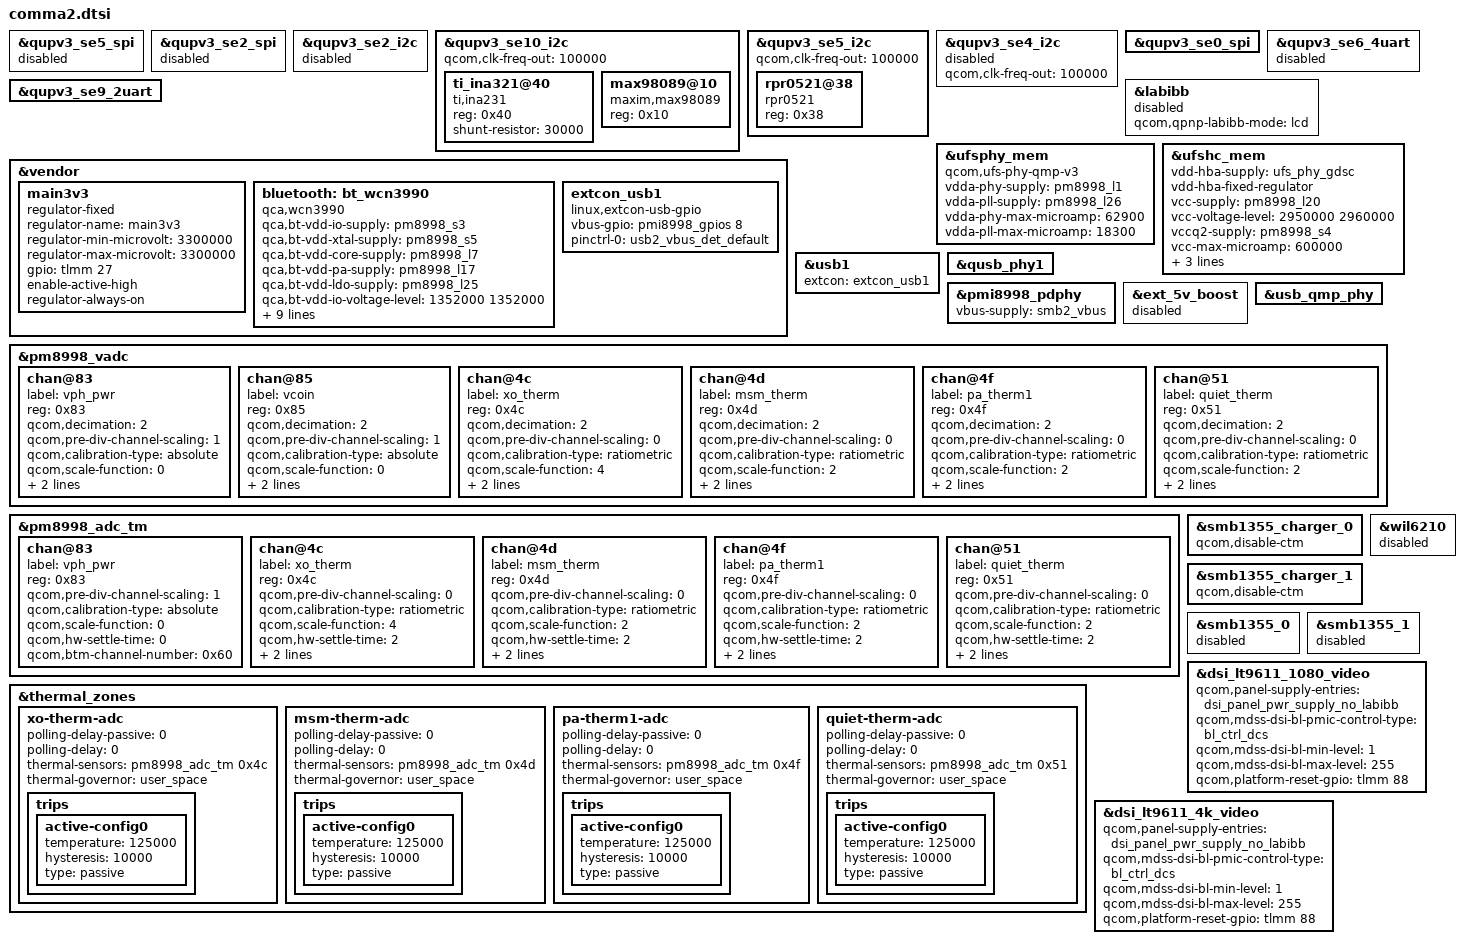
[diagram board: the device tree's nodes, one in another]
#include <dt-bindings/gpio/gpio.h>
#include "sdm845-pmic-overlay.dtsi"
#include "sdm845-pinctrl-overlay.dtsi"
#include "sdm845-camera-sensor-mtp.dtsi"

/* disable the SPI */
&qupv3_se5_spi {
	status = "disabled";
};

&qupv3_se2_spi {
	status = "disabled";
};

&qupv3_se2_i2c {
	status = "disabled";
};

/* audio and power monitor(ina230) I2C, /dev/i2c-0 */
&qupv3_se10_i2c {
  status = "ok";
  qcom,clk-freq-out = <100000>;

  #include "smb1355.dtsi"

  ti_ina321@40 {
    compatible = "ti,ina231";
    reg = <0x40>;
    /* value is 30mOhm, measured in uohms */
    shunt-resistor = <30000>;
  };

  max98089@10 {
    compatible = "maxim,max98089";
    reg = <0x10>;  /* slave address 0x20 for write, 0x21 for read */
    status = "okay";
  };
};

/* light(RPR-0521RS) and touch panel I2C, /dev/i2c-2 */
&qupv3_se5_i2c {
  status = "ok";
  qcom,clk-freq-out = <100000>;

  rpr0521@38 {
    compatible = "rpr0521";
    reg = <0x38>;
  };
};

/* second home of the sensors besides SSC, BLSP4 on tici */
&qupv3_se4_i2c {
  status = "disabled";
  //status = "ok";
  qcom,clk-freq-out = <100000>;
};

/* panda SPI */
&qupv3_se0_spi {
	status = "ok";
};

/* GPS UART */
&qupv3_se6_4uart {
	status = "disabled";
};

/* debug UART */
&qupv3_se9_2uart {
	status = "ok";
};

/* regulators */

&vendor {
  main3v3: main3v3 {
    status = "ok";

    compatible = "regulator-fixed";
    regulator-name = "main3v3";
    regulator-min-microvolt = <3300000>;
    regulator-max-microvolt = <3300000>;

    gpio = <&tlmm 27 0>;
    enable-active-high;
    regulator-always-on;
  };
};

/* IMUs are on SSC i2c, have to interact with that firmware */

&vendor {
	bluetooth: bt_wcn3990 {
		compatible = "qca,wcn3990";
		qca,bt-vdd-io-supply = <&pm8998_s3>;
		qca,bt-vdd-xtal-supply = <&pm8998_s5>;
		qca,bt-vdd-core-supply = <&pm8998_l7>;
		qca,bt-vdd-pa-supply = <&pm8998_l17>;
		qca,bt-vdd-ldo-supply = <&pm8998_l25>;

		qca,bt-vdd-io-voltage-level = <1352000 1352000>;
		qca,bt-vdd-xtal-voltage-level = <2040000 2040000>;
		qca,bt-vdd-core-voltage-level = <1800000 1800000>;
		qca,bt-vdd-pa-voltage-level = <1304000 1304000>;
		qca,bt-vdd-ldo-voltage-level = <3312000 3312000>;

		qca,bt-vdd-io-current-level = <1>; /* LPM/PFM */
		qca,bt-vdd-xtal-current-level = <1>; /* LPM/PFM */
		qca,bt-vdd-core-current-level = <1>; /* LPM/PFM */
		qca,bt-vdd-pa-current-level = <1>; /* LPM/PFM */
		qca,bt-vdd-ldo-current-level = <1>; /* LPM/PFM */
	};

	extcon_usb1: extcon_usb1 {
		compatible = "linux,extcon-usb-gpio";
		vbus-gpio = <&pmi8998_gpios 8 GPIO_ACTIVE_HIGH>;

		pinctrl-names = "default";
		pinctrl-0 = <&usb2_vbus_det_default>;
	};
};

&labibb {
	status = "disabled";
	qcom,qpnp-labibb-mode = "lcd";
};

&ufsphy_mem {
	compatible = "qcom,ufs-phy-qmp-v3";

	vdda-phy-supply = <&pm8998_l1>; /* 0.88v */
	vdda-pll-supply = <&pm8998_l26>; /* 1.2v */
	vdda-phy-max-microamp = <62900>;
	vdda-pll-max-microamp = <18300>;

	status = "ok";
};

&ufshc_mem {
	vdd-hba-supply = <&ufs_phy_gdsc>;
	vdd-hba-fixed-regulator;
	vcc-supply = <&pm8998_l20>;
	vcc-voltage-level = <2950000 2960000>;
	vccq2-supply = <&pm8998_s4>;
	vcc-max-microamp = <600000>;
	vccq2-max-microamp = <600000>;

	qcom,vddp-ref-clk-supply = <&pm8998_l2>;
	qcom,vddp-ref-clk-max-microamp = <100>;

	status = "ok";
};

&usb1 {
	status = "okay";
	extcon = <&extcon_usb1>;
};

&qusb_phy1 {
	status = "okay";
};

&pmi8998_pdphy {
	vbus-supply = <&smb2_vbus>;
};

&ext_5v_boost {
	status = "disabled";
};

&usb_qmp_phy {
	status = "okay";
};

&pm8998_vadc {
	chan@83 {
		label = "vph_pwr";
		reg = <0x83>;
		qcom,decimation = <2>;
		qcom,pre-div-channel-scaling = <1>;
		qcom,calibration-type = "absolute";
		qcom,scale-function = <0>;
		qcom,hw-settle-time = <0>;
		qcom,fast-avg-setup = <0>;
	};

	chan@85 {
		label = "vcoin";
		reg = <0x85>;
		qcom,decimation = <2>;
		qcom,pre-div-channel-scaling = <1>;
		qcom,calibration-type = "absolute";
		qcom,scale-function = <0>;
		qcom,hw-settle-time = <0>;
		qcom,fast-avg-setup = <0>;
	};

	chan@4c {
		label = "xo_therm";
		reg = <0x4c>;
		qcom,decimation = <2>;
		qcom,pre-div-channel-scaling = <0>;
		qcom,calibration-type = "ratiometric";
		qcom,scale-function = <4>;
		qcom,hw-settle-time = <2>;
		qcom,fast-avg-setup = <0>;
	};

	chan@4d {
		label = "msm_therm";
		reg = <0x4d>;
		qcom,decimation = <2>;
		qcom,pre-div-channel-scaling = <0>;
		qcom,calibration-type = "ratiometric";
		qcom,scale-function = <2>;
		qcom,hw-settle-time = <2>;
		qcom,fast-avg-setup = <0>;
	};

	chan@4f {
		label = "pa_therm1";
		reg = <0x4f>;
		qcom,decimation = <2>;
		qcom,pre-div-channel-scaling = <0>;
		qcom,calibration-type = "ratiometric";
		qcom,scale-function = <2>;
		qcom,hw-settle-time = <2>;
		qcom,fast-avg-setup = <0>;
	};

	chan@51 {
		label = "quiet_therm";
		reg = <0x51>;
		qcom,decimation = <2>;
		qcom,pre-div-channel-scaling = <0>;
		qcom,calibration-type = "ratiometric";
		qcom,scale-function = <2>;
		qcom,hw-settle-time = <2>;
		qcom,fast-avg-setup = <0>;
	};
};

&pm8998_adc_tm {
	chan@83 {
		label = "vph_pwr";
		reg = <0x83>;
		qcom,pre-div-channel-scaling = <1>;
		qcom,calibration-type = "absolute";
		qcom,scale-function = <0>;
		qcom,hw-settle-time = <0>;
		qcom,btm-channel-number = <0x60>;
	};

	chan@4c {
		label = "xo_therm";
		reg = <0x4c>;
		qcom,pre-div-channel-scaling = <0>;
		qcom,calibration-type = "ratiometric";
		qcom,scale-function = <4>;
		qcom,hw-settle-time = <2>;
		qcom,btm-channel-number = <0x68>;
		qcom,thermal-node;
	};

	chan@4d {
		label = "msm_therm";
		reg = <0x4d>;
		qcom,pre-div-channel-scaling = <0>;
		qcom,calibration-type = "ratiometric";
		qcom,scale-function = <2>;
		qcom,hw-settle-time = <2>;
		qcom,btm-channel-number = <0x70>;
		qcom,thermal-node;
	};

	chan@4f {
		label = "pa_therm1";
		reg = <0x4f>;
		qcom,pre-div-channel-scaling = <0>;
		qcom,calibration-type = "ratiometric";
		qcom,scale-function = <2>;
		qcom,hw-settle-time = <2>;
		qcom,btm-channel-number = <0x78>;
		qcom,thermal-node;
	};

	chan@51 {
		label = "quiet_therm";
		reg = <0x51>;
		qcom,pre-div-channel-scaling = <0>;
		qcom,calibration-type = "ratiometric";
		qcom,scale-function = <2>;
		qcom,hw-settle-time = <2>;
		qcom,btm-channel-number = <0x80>;
		qcom,thermal-node;
	};
};

&thermal_zones {
	xo-therm-adc {
		polling-delay-passive = <0>;
		polling-delay = <0>;
		thermal-sensors = <&pm8998_adc_tm 0x4c>;
		thermal-governor = "user_space";

		trips {
			active-config0 {
				temperature = <125000>;
				hysteresis = <10000>;
				type = "passive";
			};
		};
	};

	msm-therm-adc {
		polling-delay-passive = <0>;
		polling-delay = <0>;
		thermal-sensors = <&pm8998_adc_tm 0x4d>;
		thermal-governor = "user_space";

		trips {
			active-config0 {
				temperature = <125000>;
				hysteresis = <10000>;
				type = "passive";
			};
		};
	};

	pa-therm1-adc {
		polling-delay-passive = <0>;
		polling-delay = <0>;
		thermal-sensors = <&pm8998_adc_tm 0x4f>;
		thermal-governor = "user_space";

		trips {
			active-config0 {
				temperature = <125000>;
				hysteresis = <10000>;
				type = "passive";
			};
		};
	};

	quiet-therm-adc {
		polling-delay-passive = <0>;
		polling-delay = <0>;
		thermal-sensors = <&pm8998_adc_tm 0x51>;
		thermal-governor = "user_space";

		trips {
			active-config0 {
				temperature = <125000>;
				hysteresis = <10000>;
				type = "passive";
			};
		};
	};
};

&smb1355_charger_0 {
	status = "ok";
	qcom,disable-ctm;
};

&smb1355_charger_1 {
	status = "ok";
	qcom,disable-ctm;
};

&wil6210 {
	status = "disable";
};

&smb1355_0 {
	status = "disabled";
};

&smb1355_1 {
	status = "disabled";
};


/* broken, remove later */

&dsi_lt9611_1080_video {
		qcom,panel-supply-entries = <&dsi_panel_pwr_supply_no_labibb>;
		qcom,mdss-dsi-bl-pmic-control-type = "bl_ctrl_dcs";
		qcom,mdss-dsi-bl-min-level = <1>;
		qcom,mdss-dsi-bl-max-level = <255>;
		//qcom,mdss-dsi-mode-sel-gpio-state = "single_port";
		//qcom,panel-mode-gpio = <&tlmm 52 0>;
		qcom,platform-reset-gpio = <&tlmm 88 0>;
	
};

&dsi_lt9611_4k_video {
	qcom,panel-supply-entries = <&dsi_panel_pwr_supply_no_labibb>;
	qcom,mdss-dsi-bl-pmic-control-type = "bl_ctrl_dcs";
	qcom,mdss-dsi-bl-min-level = <1>;
	qcom,mdss-dsi-bl-max-level = <255>;
	//qcom,mdss-dsi-mode-sel-gpio-state = "dual_port";
	//qcom,panel-mode-gpio = <&tlmm 52 0>;
	qcom,platform-reset-gpio = <&tlmm 88 0>;

};

